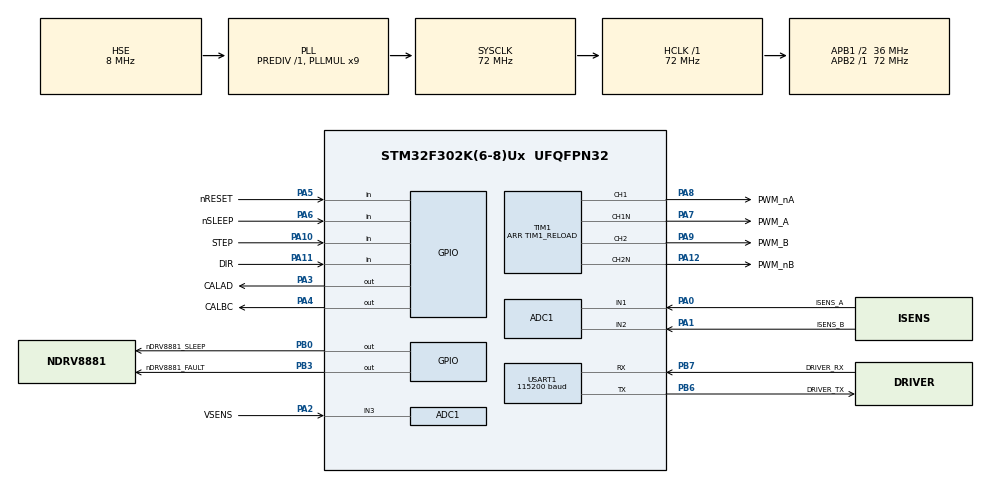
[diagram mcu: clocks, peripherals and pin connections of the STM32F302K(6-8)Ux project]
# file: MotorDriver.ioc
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ADC1.Channel-0\#ChannelRegularConversion=ADC_CHANNEL_1
ADC1.Channel-1\#ChannelRegularConversion=ADC_CHANNEL_2
ADC1.Channel-4\#ChannelRegularConversion=ADC_CHANNEL_3
ADC1.Channel-5\#ChannelRegularConversion=ADC_CHANNEL_VREFINT
ADC1.ClockPrescaler=ADC_CLOCK_SYNC_PCLK_DIV1
ADC1.ContinuousConvMode=DISABLE
ADC1.DMAContinuousRequests=ENABLE
ADC1.EOCSelection=ADC_EOC_SEQ_CONV
ADC1.EnableInjectedConversion=DISABLE
ADC1.ExternalTrigConv=ADC_EXTERNALTRIGCONV_T2_TRGO
ADC1.ExternalTrigConvEdge=ADC_EXTERNALTRIGCONVEDGE_RISING
ADC1.NbrOfConversion=4
ADC1.NbrOfConversionFlag=1
ADC1.Offset-0\#ChannelRegularConversion=0
ADC1.Offset-1\#ChannelRegularConversion=0
ADC1.Offset-4\#ChannelRegularConversion=0
ADC1.Offset-5\#ChannelRegularConversion=0
ADC1.OffsetNumber-0\#ChannelRegularConversion=ADC_OFFSET_NONE
ADC1.OffsetNumber-1\#ChannelRegularConversion=ADC_OFFSET_NONE
ADC1.OffsetNumber-4\#ChannelRegularConversion=ADC_OFFSET_NONE
ADC1.OffsetNumber-5\#ChannelRegularConversion=ADC_OFFSET_NONE
ADC1.Rank-0\#ChannelRegularConversion=1
ADC1.Rank-1\#ChannelRegularConversion=2
ADC1.Rank-4\#ChannelRegularConversion=3
ADC1.Rank-5\#ChannelRegularConversion=4
ADC1.SamplingTime-0\#ChannelRegularConversion=ADC_SAMPLETIME_7CYCLES_5
ADC1.SamplingTime-1\#ChannelRegularConversion=ADC_SAMPLETIME_7CYCLES_5
ADC1.SamplingTime-4\#ChannelRegularConversion=ADC_SAMPLETIME_7CYCLES_5
ADC1.SamplingTime-5\#ChannelRegularConversion=ADC_SAMPLETIME_7CYCLES_5
ADC1.SubFamily=STM32F302x8
ADC1.master=1
Dma.ADC1.0.Direction=DMA_PERIPH_TO_MEMORY
Dma.ADC1.0.Instance=DMA1_Channel1
Dma.ADC1.0.MemDataAlignment=DMA_MDATAALIGN_HALFWORD
Dma.ADC1.0.MemInc=DMA_MINC_ENABLE
Dma.ADC1.0.Mode=DMA_CIRCULAR
Dma.ADC1.0.PeriphDataAlignment=DMA_PDATAALIGN_HALFWORD
Dma.ADC1.0.PeriphInc=DMA_PINC_DISABLE
Dma.ADC1.0.Priority=DMA_PRIORITY_VERY_HIGH
Dma.Request0=ADC1
Dma.Request1=USART1_RX
Dma.Request2=USART1_TX
Dma.USART1_RX.1.Direction=DMA_PERIPH_TO_MEMORY
Dma.USART1_RX.1.Instance=DMA1_Channel5
Dma.USART1_RX.1.MemDataAlignment=DMA_MDATAALIGN_BYTE
Dma.USART1_RX.1.MemInc=DMA_MINC_ENABLE
Dma.USART1_RX.1.Mode=DMA_CIRCULAR
Dma.USART1_RX.1.PeriphDataAlignment=DMA_PDATAALIGN_BYTE
Dma.USART1_RX.1.PeriphInc=DMA_PINC_DISABLE
Dma.USART1_RX.1.Priority=DMA_PRIORITY_HIGH
Dma.USART1_TX.2.Direction=DMA_MEMORY_TO_PERIPH
Dma.USART1_TX.2.Instance=DMA1_Channel4
Dma.USART1_TX.2.MemDataAlignment=DMA_MDATAALIGN_BYTE
Dma.USART1_TX.2.MemInc=DMA_MINC_ENABLE
Dma.USART1_TX.2.Mode=DMA_NORMAL
Dma.USART1_TX.2.PeriphDataAlignment=DMA_PDATAALIGN_BYTE
Dma.USART1_TX.2.PeriphInc=DMA_PINC_DISABLE
Dma.USART1_TX.2.Priority=DMA_PRIORITY_MEDIUM
Mcu.Family=STM32F3
Mcu.Name=STM32F302K(6-8)Ux
Mcu.Package=UFQFPN32
Mcu.UserConstants=PWM_FREQUENCY,22000;TIM1_RELOAD,(TIM1_CLOCK_FREQUENCY / PWM_FREQUENCY);SAMPLES_PER_PERIOD,8;SAMPLING_FREQUENCY,(SAMPLES_PER_PERIOD * PWM_FREQUENCY);TIM2_RELOAD,(TIM2_CLOCK_FREQUENCY / SAMPLING_FREQUENCY);TIM2_CLOCK_FREQUENCY,72000000;TIM1_CLOCK_FREQUENCY,144000000;CONTROL_FREQUENCY,10000;TIM6_CLOCK_FREQUENCY,72000000;TIM6_RELOAD,(TIM6_CLOCK_FREQUENCY / CONTROL_FREQUENCY)
NVIC.DMA1_Channel1_IRQn=true\:12\:0\:true\:false\:true\:false\:true
NVIC.DMA1_Channel4_IRQn=true\:13\:0\:true\:false\:true\:false\:true
NVIC.DMA1_Channel5_IRQn=true\:14\:0\:true\:false\:true\:false\:true
NVIC.PriorityGroup=NVIC_PRIORITYGROUP_4
NVIC.TIM6_DAC_IRQn=true\:0\:0\:false\:false\:true\:true\:true
NVIC.USART1_IRQn=true\:15\:0\:true\:false\:true\:true\:true
PA0.GPIO_Label=ISENS_A
PA0.Mode=IN1-Single-Ended
PA0.Signal=ADC1_IN1
PA1.GPIO_Label=ISENS_B
PA1.Mode=IN2-Single-Ended
PA1.Signal=ADC1_IN2
PA10.GPIO_Label=STEP
PA10.Signal=GPIO_Input
PA11.GPIO_Label=DIR
PA11.Signal=GPIO_Input
PA12.GPIO_Label=PWM_nB
PA12.Mode=Output Compare2 CH2 CH2N
PA12.Signal=TIM1_CH2N
PA13.Mode=Serial_Wire
PA13.Signal=SYS_JTMS-SWDIO
PA14.Mode=Serial_Wire
PA14.Signal=SYS_JTCK-SWCLK
PA2.GPIO_Label=VSENS
PA2.Signal=SharedAnalog_PA2
PA3.GPIO_Label=CALAD
PA3.Signal=GPIO_Output
PA4.GPIO_Label=CALBC
PA4.Signal=GPIO_Output
PA5.GPIO_Label=nRESET
PA5.Signal=GPIO_Input
PA6.GPIO_Label=nSLEEP
PA6.Signal=GPIO_Input
PA7.GPIO_Label=PWM_A
PA7.Mode=Output Compare1 CH1 CH1N
PA7.Signal=TIM1_CH1N
PA8.GPIO_Label=PWM_nA
PA8.Signal=S_TIM1_CH1
PA9.GPIO_Label=PWM_B
PA9.Signal=S_TIM1_CH2
PB0.GPIO_Label=nDRV8881_SLEEP
PB0.Signal=GPIO_Output
PB3.GPIO_Label=nDRV8881_FAULT
PB3.Signal=GPIO_Output
PB6.GPIO_FM6=__NULL
PB6.GPIO_Label=DRIVER_TX
PB6.Mode=Asynchronous
PB6.Signal=USART1_TX
PB7.GPIO_Label=DRIVER_RX
PB7.Mode=Asynchronous
PB7.Signal=USART1_RX
PF0-OSC_IN.Mode=HSE-External-Oscillator
PF0-OSC_IN.Signal=RCC_OSC_IN
PF1-OSC_OUT.Mode=HSE-External-Oscillator
PF1-OSC_OUT.Signal=RCC_OSC_OUT
ProjectManager.HeapSize=0x200
ProjectManager.StackSize=0x400
ProjectManager.TargetToolchain=Makefile
RCC.AHBFreq_Value=72000000
RCC.APB1CLKDivider=RCC_HCLK_DIV2
RCC.APB1Freq_Value=36000000
RCC.APB1TimFreq_Value=72000000
RCC.APB2Freq_Value=72000000
RCC.APB2TimFreq_Value=72000000
RCC.CortexFreq_Value=72000000
RCC.HCLKFreq_Value=72000000
RCC.HSE_VALUE=8000000
RCC.HSI_VALUE=8000000
RCC.PLLMUL=RCC_PLL_MUL9
RCC.PLLSourceVirtual=RCC_PLLSOURCE_HSE
RCC.SYSCLKFreq_VALUE=72000000
RCC.SYSCLKSourceVirtual=RCC_SYSCLKSOURCE_PLLCLK
RCC.TIM1Selection=RCC_TIM1CLK_PLLCLK
RCC.USBFreq_Value=72000000
RCC.Usart1ClockSelection=RCC_USART1CLKSOURCE_SYSCLK
SH.S_TIM1_CH1.0=TIM1_CH1,Output Compare1 CH1 CH1N
SH.S_TIM1_CH2.0=TIM1_CH2,Output Compare2 CH2 CH2N
SH.SharedAnalog_PA2.0=GPIO_Analog
SH.SharedAnalog_PA2.1=ADC1_IN3,IN3-Single-Ended
TIM1.AutoReloadPreload=TIM_AUTORELOAD_PRELOAD_ENABLE
TIM1.Channel-Output\ Compare1\ CH1\ CH1N=TIM_CHANNEL_1
TIM1.Channel-Output\ Compare2\ CH2\ CH2N=TIM_CHANNEL_2
TIM1.OCIdleState_1=TIM_OCIDLESTATE_RESET
TIM1.OCIdleState_2=TIM_OCIDLESTATE_RESET
TIM1.OCMode_1=TIM_OCMODE_TOGGLE
TIM1.OCMode_2=TIM_OCMODE_TOGGLE
TIM1.OCNIdleState_1=TIM_OCNIDLESTATE_RESET
TIM1.OCNIdleState_2=TIM_OCNIDLESTATE_RESET
TIM1.OCNPolarity_1=TIM_OCNPOLARITY_LOW
TIM1.OCNPolarity_2=TIM_OCNPOLARITY_LOW
TIM1.Period=TIM1_RELOAD
TIM1.TIM_MasterOutputTrigger=TIM_TRGO_UPDATE
TIM1.TIM_MasterSlaveMode=TIM_MASTERSLAVEMODE_DISABLE
TIM2.Period=TIM2_RELOAD
TIM2.TIM_MasterOutputTrigger=TIM_TRGO_UPDATE
TIM2.TIM_MasterSlaveMode=TIM_MASTERSLAVEMODE_ENABLE
TIM6.Period=TIM6_RELOAD
USART1.BaudRate=115200
USART1.VirtualMode-Asynchronous=VM_ASYNC
VP_ADC1_Vref_Input.Mode=IN-Vrefint
VP_CRC_VS_CRC.Mode=CRC_Activate
VP_TIM1_VS_ClockSourceINT.Mode=Internal
VP_TIM1_VS_ClockSourceITR.Mode=TriggerSource_ITR1
VP_TIM2_VS_ClockSourceINT.Mode=Internal
VP_TIM2_VS_ClockSourceITR.Mode=TriggerSource_ITR0
VP_TIM2_VS_ControllerModeGated.Mode=Gated Mode
VP_TIM6_VS_ClockSourceINT.Mode=Enable_Timer
board=custom

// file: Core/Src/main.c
/* USER CODE BEGIN Header */
/**
  ******************************************************************************
  * @file           : main.c
  * @brief          : Main program body
  ******************************************************************************
  ** This notice applies to any and all portions of this file
  * that are not between comment pairs USER CODE BEGIN and
  * USER CODE END. Other portions of this file, whether
  * inserted by the user or by software development tools
  * are owned by their respective copyright owners.
  *
  * COPYRIGHT(c) 2018 STMicroelectronics
  *
  * Redistribution and use in source and binary forms, with or without modification,
  * are permitted provided that the following conditions are met:
  *   1. Redistributions of source code must retain the above copyright notice,
  *      this list of conditions and the following disclaimer.
  *   2. Redistributions in binary form must reproduce the above copyright notice,
  *      this list of conditions and the following disclaimer in the documentation
  *      and/or other materials provided with the distribution.
  *   3. Neither the name of STMicroelectronics nor the names of its contributors
  *      may be used to endorse or promote products derived from this software
  *      without specific prior written permission.
  *
  * THIS SOFTWARE IS PROVIDED BY THE COPYRIGHT HOLDERS AND CONTRIBUTORS "AS IS"
  * AND ANY EXPRESS OR IMPLIED WARRANTIES, INCLUDING, BUT NOT LIMITED TO, THE
  * IMPLIED WARRANTIES OF MERCHANTABILITY AND FITNESS FOR A PARTICULAR PURPOSE ARE
  * DISCLAIMED. IN NO EVENT SHALL THE COPYRIGHT HOLDER OR CONTRIBUTORS BE LIABLE
  * FOR ANY DIRECT, INDIRECT, INCIDENTAL, SPECIAL, EXEMPLARY, OR CONSEQUENTIAL
  * DAMAGES (INCLUDING, BUT NOT LIMITED TO, PROCUREMENT OF SUBSTITUTE GOODS OR
  * SERVICES; LOSS OF USE, DATA, OR PROFITS; OR BUSINESS INTERRUPTION) HOWEVER
  * CAUSED AND ON ANY THEORY OF LIABILITY, WHETHER IN CONTRACT, STRICT LIABILITY,
  * OR TORT (INCLUDING NEGLIGENCE OR OTHERWISE) ARISING IN ANY WAY OUT OF THE USE
  * OF THIS SOFTWARE, EVEN IF ADVISED OF THE POSSIBILITY OF SUCH DAMAGE.
  *
  ******************************************************************************
  */
/* USER CODE END Header */

#include "main.h"

ADC_HandleTypeDef hadc1;
DMA_HandleTypeDef hdma_adc1;

CRC_HandleTypeDef hcrc;

TIM_HandleTypeDef htim1;
TIM_HandleTypeDef htim2;
TIM_HandleTypeDef htim6;

UART_HandleTypeDef huart1;
DMA_HandleTypeDef hdma_usart1_rx;
DMA_HandleTypeDef hdma_usart1_tx;

/* USER CODE BEGIN PV */
static float SineTable[];
/* USER CODE END PV */

void SystemClock_Config(void);
static void MX_GPIO_Init(void);
static void MX_DMA_Init(void);
static void MX_TIM1_Init(void);
static void MX_ADC1_Init(void);
static void MX_CRC_Init(void);
static void MX_USART1_UART_Init(void);
static void MX_TIM2_Init(void);
static void MX_TIM6_Init(void);

int main(void)
{

  /* MCU Configuration--------------------------------------------------------*/

  /* Reset of all peripherals, Initializes the Flash interface and the Systick. */
  HAL_Init();

  /* Configure the system clock */
  SystemClock_Config();

  /* Initialize all configured peripherals */
  MX_GPIO_Init();
  MX_DMA_Init();
  MX_TIM1_Init();
  MX_ADC1_Init();
  MX_CRC_Init();
  MX_USART1_UART_Init();
  MX_TIM2_Init();
  MX_TIM6_Init();

  /* Infinite loop */
  while (1)
  {

  }
}

void SystemClock_Config(void)
{
  RCC_OscInitTypeDef RCC_OscInitStruct = {0};
  RCC_ClkInitTypeDef RCC_ClkInitStruct = {0};
  RCC_PeriphCLKInitTypeDef PeriphClkInit = {0};

  /** Initializes the CPU, AHB and APB busses clocks
  */
  RCC_OscInitStruct.OscillatorType = RCC_OSCILLATORTYPE_HSE;
  RCC_OscInitStruct.HSEState = RCC_HSE_ON;
  RCC_OscInitStruct.HSEPredivValue = RCC_HSE_PREDIV_DIV1;
  RCC_OscInitStruct.HSIState = RCC_HSI_ON;
  RCC_OscInitStruct.PLL.PLLState = RCC_PLL_ON;
  RCC_OscInitStruct.PLL.PLLSource = RCC_PLLSOURCE_HSE;
  RCC_OscInitStruct.PLL.PLLMUL = RCC_PLL_MUL9;
  if (HAL_RCC_OscConfig(&RCC_OscInitStruct) != HAL_OK)
  {
    Error_Handler();
  }
  /** Initializes the CPU, AHB and APB busses clocks
  */
  RCC_ClkInitStruct.ClockType = RCC_CLOCKTYPE_HCLK|RCC_CLOCKTYPE_SYSCLK
                              |RCC_CLOCKTYPE_PCLK1|RCC_CLOCKTYPE_PCLK2;
  RCC_ClkInitStruct.SYSCLKSource = RCC_SYSCLKSOURCE_PLLCLK;
  RCC_ClkInitStruct.AHBCLKDivider = RCC_SYSCLK_DIV1;
  RCC_ClkInitStruct.APB1CLKDivider = RCC_HCLK_DIV2;
  RCC_ClkInitStruct.APB2CLKDivider = RCC_HCLK_DIV1;

  if (HAL_RCC_ClockConfig(&RCC_ClkInitStruct, FLASH_LATENCY_2) != HAL_OK)
  {
    Error_Handler();
  }
  PeriphClkInit.PeriphClockSelection = RCC_PERIPHCLK_USART1|RCC_PERIPHCLK_TIM1;
  PeriphClkInit.Usart1ClockSelection = RCC_USART1CLKSOURCE_SYSCLK;
  PeriphClkInit.Tim1ClockSelection = RCC_TIM1CLK_PLLCLK;
  if (HAL_RCCEx_PeriphCLKConfig(&PeriphClkInit) != HAL_OK)
  {
    Error_Handler();
  }
}

static void MX_ADC1_Init(void)
{

  ADC_ChannelConfTypeDef sConfig = {0};

  /** Common config
  */
  hadc1.Instance = ADC1;
  hadc1.Init.ClockPrescaler = ADC_CLOCK_SYNC_PCLK_DIV1;
  hadc1.Init.Resolution = ADC_RESOLUTION_12B;
  hadc1.Init.ScanConvMode = ADC_SCAN_ENABLE;
  hadc1.Init.ContinuousConvMode = DISABLE;
  hadc1.Init.DiscontinuousConvMode = DISABLE;
  hadc1.Init.ExternalTrigConvEdge = ADC_EXTERNALTRIGCONVEDGE_RISING;
  hadc1.Init.ExternalTrigConv = ADC_EXTERNALTRIGCONV_T2_TRGO;
  hadc1.Init.DataAlign = ADC_DATAALIGN_RIGHT;
  hadc1.Init.NbrOfConversion = 4;
  hadc1.Init.DMAContinuousRequests = ENABLE;
  hadc1.Init.EOCSelection = ADC_EOC_SEQ_CONV;
  hadc1.Init.LowPowerAutoWait = DISABLE;
  hadc1.Init.Overrun = ADC_OVR_DATA_OVERWRITTEN;
  if (HAL_ADC_Init(&hadc1) != HAL_OK)
  {
    Error_Handler();
  }
  /** Configure Regular Channel
  */
  sConfig.Channel = ADC_CHANNEL_1;
  sConfig.Rank = ADC_REGULAR_RANK_1;
  sConfig.SingleDiff = ADC_SINGLE_ENDED;
  sConfig.SamplingTime = ADC_SAMPLETIME_7CYCLES_5;
  sConfig.OffsetNumber = ADC_OFFSET_NONE;
  sConfig.Offset = 0;
  if (HAL_ADC_ConfigChannel(&hadc1, &sConfig) != HAL_OK)
  {
    Error_Handler();
  }
  /** Configure Regular Channel
  */
  sConfig.Channel = ADC_CHANNEL_2;
  sConfig.Rank = ADC_REGULAR_RANK_2;
  if (HAL_ADC_ConfigChannel(&hadc1, &sConfig) != HAL_OK)
  {
    Error_Handler();
  }
  /** Configure Regular Channel
  */
  sConfig.Channel = ADC_CHANNEL_3;
  sConfig.Rank = ADC_REGULAR_RANK_3;
  if (HAL_ADC_ConfigChannel(&hadc1, &sConfig) != HAL_OK)
  {
    Error_Handler();
  }
  /** Configure Regular Channel
  */
  sConfig.Channel = ADC_CHANNEL_VREFINT;
  sConfig.Rank = ADC_REGULAR_RANK_4;
  if (HAL_ADC_ConfigChannel(&hadc1, &sConfig) != HAL_OK)
  {
    Error_Handler();
  }

}

static void MX_CRC_Init(void)
{

  hcrc.Instance = CRC;
  hcrc.Init.DefaultPolynomialUse = DEFAULT_POLYNOMIAL_ENABLE;
  hcrc.Init.DefaultInitValueUse = DEFAULT_INIT_VALUE_ENABLE;
  hcrc.Init.InputDataInversionMode = CRC_INPUTDATA_INVERSION_NONE;
  hcrc.Init.OutputDataInversionMode = CRC_OUTPUTDATA_INVERSION_DISABLE;
  hcrc.InputDataFormat = CRC_INPUTDATA_FORMAT_BYTES;
  if (HAL_CRC_Init(&hcrc) != HAL_OK)
  {
    Error_Handler();
  }

}

static void MX_TIM1_Init(void)
{

  TIM_ClockConfigTypeDef sClockSourceConfig = {0};
  TIM_SlaveConfigTypeDef sSlaveConfig = {0};
  TIM_MasterConfigTypeDef sMasterConfig = {0};
  TIM_OC_InitTypeDef sConfigOC = {0};
  TIM_BreakDeadTimeConfigTypeDef sBreakDeadTimeConfig = {0};

  htim1.Instance = TIM1;
  htim1.Init.Prescaler = 0;
  htim1.Init.CounterMode = TIM_COUNTERMODE_UP;
  htim1.Init.Period = TIM1_RELOAD;
  htim1.Init.ClockDivision = TIM_CLOCKDIVISION_DIV1;
  htim1.Init.RepetitionCounter = 0;
  htim1.Init.AutoReloadPreload = TIM_AUTORELOAD_PRELOAD_ENABLE;
  if (HAL_TIM_Base_Init(&htim1) != HAL_OK)
  {
    Error_Handler();
  }
  sClockSourceConfig.ClockSource = TIM_CLOCKSOURCE_INTERNAL;
  if (HAL_TIM_ConfigClockSource(&htim1, &sClockSourceConfig) != HAL_OK)
  {
    Error_Handler();
  }
  if (HAL_TIM_OC_Init(&htim1) != HAL_OK)
  {
    Error_Handler();
  }
  sSlaveConfig.SlaveMode = TIM_SLAVEMODE_DISABLE;
  sSlaveConfig.InputTrigger = TIM_TS_ITR1;
  if (HAL_TIM_SlaveConfigSynchronization(&htim1, &sSlaveConfig) != HAL_OK)
  {
    Error_Handler();
  }
  sMasterConfig.MasterOutputTrigger = TIM_TRGO_UPDATE;
  sMasterConfig.MasterOutputTrigger2 = TIM_TRGO2_RESET;
  sMasterConfig.MasterSlaveMode = TIM_MASTERSLAVEMODE_DISABLE;
  if (HAL_TIMEx_MasterConfigSynchronization(&htim1, &sMasterConfig) != HAL_OK)
  {
    Error_Handler();
  }
  sConfigOC.OCMode = TIM_OCMODE_TOGGLE;
  sConfigOC.Pulse = 0;
  sConfigOC.OCPolarity = TIM_OCPOLARITY_HIGH;
  sConfigOC.OCNPolarity = TIM_OCNPOLARITY_LOW;
  sConfigOC.OCFastMode = TIM_OCFAST_DISABLE;
  sConfigOC.OCIdleState = TIM_OCIDLESTATE_RESET;
  sConfigOC.OCNIdleState = TIM_OCNIDLESTATE_RESET;
  if (HAL_TIM_OC_ConfigChannel(&htim1, &sConfigOC, TIM_CHANNEL_1) != HAL_OK)
  {
    Error_Handler();
  }
  if (HAL_TIM_OC_ConfigChannel(&htim1, &sConfigOC, TIM_CHANNEL_2) != HAL_OK)
  {
    Error_Handler();
  }
  sBreakDeadTimeConfig.OffStateRunMode = TIM_OSSR_DISABLE;
  sBreakDeadTimeConfig.OffStateIDLEMode = TIM_OSSI_DISABLE;
  sBreakDeadTimeConfig.LockLevel = TIM_LOCKLEVEL_OFF;
  sBreakDeadTimeConfig.DeadTime = 0;
  sBreakDeadTimeConfig.BreakState = TIM_BREAK_DISABLE;
  sBreakDeadTimeConfig.BreakPolarity = TIM_BREAKPOLARITY_HIGH;
  sBreakDeadTimeConfig.BreakFilter = 0;
  sBreakDeadTimeConfig.Break2State = TIM_BREAK2_DISABLE;
  sBreakDeadTimeConfig.Break2Polarity = TIM_BREAK2POLARITY_HIGH;
  sBreakDeadTimeConfig.Break2Filter = 0;
  sBreakDeadTimeConfig.AutomaticOutput = TIM_AUTOMATICOUTPUT_DISABLE;
  if (HAL_TIMEx_ConfigBreakDeadTime(&htim1, &sBreakDeadTimeConfig) != HAL_OK)
  {
    Error_Handler();
  }
  HAL_TIM_MspPostInit(&htim1);

}

static void MX_TIM2_Init(void)
{

  TIM_ClockConfigTypeDef sClockSourceConfig = {0};
  TIM_SlaveConfigTypeDef sSlaveConfig = {0};
  TIM_MasterConfigTypeDef sMasterConfig = {0};

  htim2.Instance = TIM2;
  htim2.Init.Prescaler = 0;
  htim2.Init.CounterMode = TIM_COUNTERMODE_UP;
  htim2.Init.Period = TIM2_RELOAD;
  htim2.Init.ClockDivision = TIM_CLOCKDIVISION_DIV1;
  htim2.Init.AutoReloadPreload = TIM_AUTORELOAD_PRELOAD_DISABLE;
  if (HAL_TIM_Base_Init(&htim2) != HAL_OK)
  {
    Error_Handler();
  }
  sClockSourceConfig.ClockSource = TIM_CLOCKSOURCE_INTERNAL;
  if (HAL_TIM_ConfigClockSource(&htim2, &sClockSourceConfig) != HAL_OK)
  {
    Error_Handler();
  }
  sSlaveConfig.SlaveMode = TIM_SLAVEMODE_GATED;
  sSlaveConfig.InputTrigger = TIM_TS_ITR0;
  if (HAL_TIM_SlaveConfigSynchronization(&htim2, &sSlaveConfig) != HAL_OK)
  {
    Error_Handler();
  }
  sMasterConfig.MasterOutputTrigger = TIM_TRGO_UPDATE;
  sMasterConfig.MasterSlaveMode = TIM_MASTERSLAVEMODE_ENABLE;
  if (HAL_TIMEx_MasterConfigSynchronization(&htim2, &sMasterConfig) != HAL_OK)
  {
    Error_Handler();
  }

}

static void MX_TIM6_Init(void)
{

  TIM_MasterConfigTypeDef sMasterConfig = {0};

  htim6.Instance = TIM6;
  htim6.Init.Prescaler = 0;
  htim6.Init.CounterMode = TIM_COUNTERMODE_UP;
  htim6.Init.Period = TIM6_RELOAD;
  htim6.Init.AutoReloadPreload = TIM_AUTORELOAD_PRELOAD_DISABLE;
  if (HAL_TIM_Base_Init(&htim6) != HAL_OK)
  {
    Error_Handler();
  }
  sMasterConfig.MasterOutputTrigger = TIM_TRGO_RESET;
  sMasterConfig.MasterSlaveMode = TIM_MASTERSLAVEMODE_DISABLE;
  if (HAL_TIMEx_MasterConfigSynchronization(&htim6, &sMasterConfig) != HAL_OK)
  {
    Error_Handler();
  }

}

static void MX_USART1_UART_Init(void)
{

  huart1.Instance = USART1;
  huart1.Init.BaudRate = 115200;
  huart1.Init.WordLength = UART_WORDLENGTH_8B;
  huart1.Init.StopBits = UART_STOPBITS_1;
  huart1.Init.Parity = UART_PARITY_NONE;
  huart1.Init.Mode = UART_MODE_TX_RX;
  huart1.Init.HwFlowCtl = UART_HWCONTROL_NONE;
  huart1.Init.OverSampling = UART_OVERSAMPLING_16;
  huart1.Init.OneBitSampling = UART_ONE_BIT_SAMPLE_DISABLE;
  huart1.AdvancedInit.AdvFeatureInit = UART_ADVFEATURE_NO_INIT;
  if (HAL_UART_Init(&huart1) != HAL_OK)
  {
    Error_Handler();
  }

}

static void MX_DMA_Init(void)
{
  /* DMA controller clock enable */
  __HAL_RCC_DMA1_CLK_ENABLE();

  /* DMA interrupt init */
  /* DMA1_Channel1_IRQn interrupt configuration */
  HAL_NVIC_SetPriority(DMA1_Channel1_IRQn, 12, 0);
  HAL_NVIC_EnableIRQ(DMA1_Channel1_IRQn);
  /* DMA1_Channel4_IRQn interrupt configuration */
  HAL_NVIC_SetPriority(DMA1_Channel4_IRQn, 13, 0);
  HAL_NVIC_EnableIRQ(DMA1_Channel4_IRQn);
  /* DMA1_Channel5_IRQn interrupt configuration */
  HAL_NVIC_SetPriority(DMA1_Channel5_IRQn, 14, 0);
  HAL_NVIC_EnableIRQ(DMA1_Channel5_IRQn);

}

static void MX_GPIO_Init(void)
{
  GPIO_InitTypeDef GPIO_InitStruct = {0};

  /* GPIO Ports Clock Enable */
  __HAL_RCC_GPIOF_CLK_ENABLE();
  __HAL_RCC_GPIOA_CLK_ENABLE();
  __HAL_RCC_GPIOB_CLK_ENABLE();

  /*Configure GPIO pin Output Level */
  HAL_GPIO_WritePin(GPIOA, CALAD_Pin|CALBC_Pin, GPIO_PIN_RESET);

  /*Configure GPIO pin Output Level */
  HAL_GPIO_WritePin(GPIOB, nDRV8881_SLEEP_Pin|nDRV8881_FAULT_Pin, GPIO_PIN_RESET);

  /*Configure GPIO pins : VSENS_Pin PA15 */
  GPIO_InitStruct.Pin = VSENS_Pin|GPIO_PIN_15;
  GPIO_InitStruct.Mode = GPIO_MODE_ANALOG;
  GPIO_InitStruct.Pull = GPIO_NOPULL;
  HAL_GPIO_Init(GPIOA, &GPIO_InitStruct);

  /*Configure GPIO pins : CALAD_Pin CALBC_Pin */
  GPIO_InitStruct.Pin = CALAD_Pin|CALBC_Pin;
  GPIO_InitStruct.Mode = GPIO_MODE_OUTPUT_PP;
  GPIO_InitStruct.Pull = GPIO_NOPULL;
  GPIO_InitStruct.Speed = GPIO_SPEED_FREQ_LOW;
  HAL_GPIO_Init(GPIOA, &GPIO_InitStruct);

  /*Configure GPIO pins : nRESET_Pin nSLEEP_Pin STEP_Pin DIR_Pin */
  GPIO_InitStruct.Pin = nRESET_Pin|nSLEEP_Pin|STEP_Pin|DIR_Pin;
  GPIO_InitStruct.Mode = GPIO_MODE_INPUT;
  GPIO_InitStruct.Pull = GPIO_NOPULL;
  HAL_GPIO_Init(GPIOA, &GPIO_InitStruct);

  /*Configure GPIO pins : nDRV8881_SLEEP_Pin nDRV8881_FAULT_Pin */
  GPIO_InitStruct.Pin = nDRV8881_SLEEP_Pin|nDRV8881_FAULT_Pin;
  GPIO_InitStruct.Mode = GPIO_MODE_OUTPUT_PP;
  GPIO_InitStruct.Pull = GPIO_NOPULL;
  GPIO_InitStruct.Speed = GPIO_SPEED_FREQ_LOW;
  HAL_GPIO_Init(GPIOB, &GPIO_InitStruct);

  /*Configure GPIO pins : PB4 PB5 */
  GPIO_InitStruct.Pin = GPIO_PIN_4|GPIO_PIN_5;
  GPIO_InitStruct.Mode = GPIO_MODE_ANALOG;
  GPIO_InitStruct.Pull = GPIO_NOPULL;
  HAL_GPIO_Init(GPIOB, &GPIO_InitStruct);

}

void Error_Handler(void)
{
}

/************************ (C) COPYRIGHT STMicroelectronics *****END OF FILE****/
